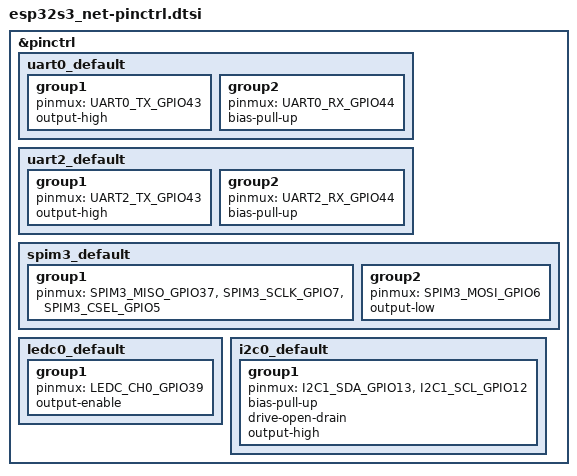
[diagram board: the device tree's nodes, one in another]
/*
 * Copyright (c) 2022 Espressif Systems (Shanghai) Co., Ltd.
 *
 * SPDX-License-Identifier: Apache-2.0
 */

#include <zephyr/dt-bindings/pinctrl/esp-pinctrl-common.h>
#include <dt-bindings/pinctrl/esp32s3-pinctrl.h>
#include <zephyr/dt-bindings/pinctrl/esp32s3-gpio-sigmap.h>

&pinctrl {
	uart0_default: uart0_default {
		group1 {
			pinmux = <UART0_TX_GPIO43>;
			output-high;
		};
		group2 {
			pinmux = <UART0_RX_GPIO44>;
			bias-pull-up;
		};
	};

	uart2_default: uart2_default {
		group1 {
			pinmux = <UART2_TX_GPIO43>;
			output-high;
		};
		group2 {
			pinmux = <UART2_RX_GPIO44>;
			bias-pull-up;
		};
	};

	spim3_default: spim3_default {
		group1 {
			pinmux = <SPIM3_MISO_GPIO37>,
				 <SPIM3_SCLK_GPIO7>,
				 <SPIM3_CSEL_GPIO5>;
		};
		group2 {
			pinmux = <SPIM3_MOSI_GPIO6>;
			output-low;
		};
	};

	ledc0_default: ledc0_default {
		group1 {
			pinmux = <LEDC_CH0_GPIO39>;
			output-enable;
		};
	};

	i2c0_default: i2c0_default {
		group1 {
			pinmux = <I2C1_SDA_GPIO13>,
				 <I2C1_SCL_GPIO12>;
			bias-pull-up;
			drive-open-drain;
			output-high;
		};
	};
};
